VERSION ""

NS_ :

BS_:

BU_:

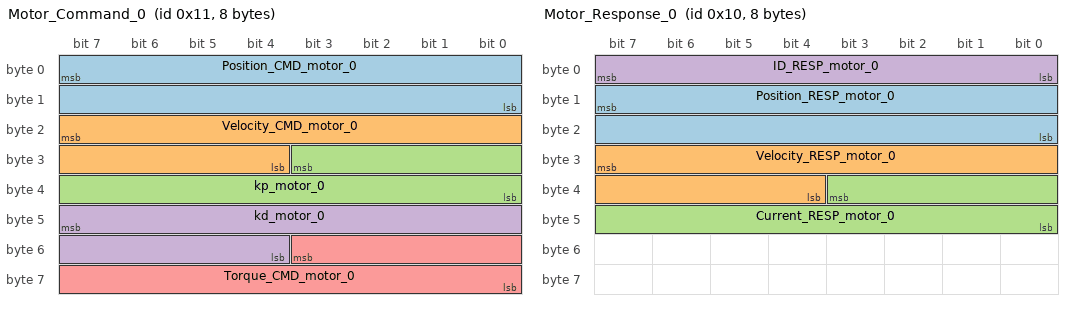
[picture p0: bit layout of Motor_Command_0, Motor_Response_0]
BO_ 17 Motor_Command_0: 8 Vector__XXX
 SG_ Position_CMD_motor_0 : 7|16@0+ (0.002914,-95.5) [0|0] "Rad" Vector__XXX
 SG_ Velocity_CMD_motor_0 : 23|12@0+ (0.02197,-45) [0|0] "Rad/s" Vector__XXX
 SG_ kp_motor_0 : 27|12@0+ (0.1221,0) [0|0] "" Vector__XXX
 SG_ kd_motor_0 : 47|12@0+ (0.001221,0) [0|0] "" Vector__XXX
 SG_ Torque_CMD_motor_0 : 51|12@0+ (0.008791,-18) [0|0] "Nm" Vector__XXX

BO_ 16 Motor_Response_0: 8 Vector__XXX
 SG_ Position_RESP_motor_0 : 15|16@0+ (0.002914,-95.5) [0|0] "Rad" Vector__XXX
 SG_ Velocity_RESP_motor_0 : 31|12@0+ (0.02197,-45) [0|0] "Rad/s" Vector__XXX
 SG_ Current_RESP_motor_0 : 35|12@0+ (0.008791,-18) [0|0] "" Vector__XXX
 SG_ ID_RESP_motor_0 : 7|8@0+ (1,0) [0|0] "" Vector__XXX

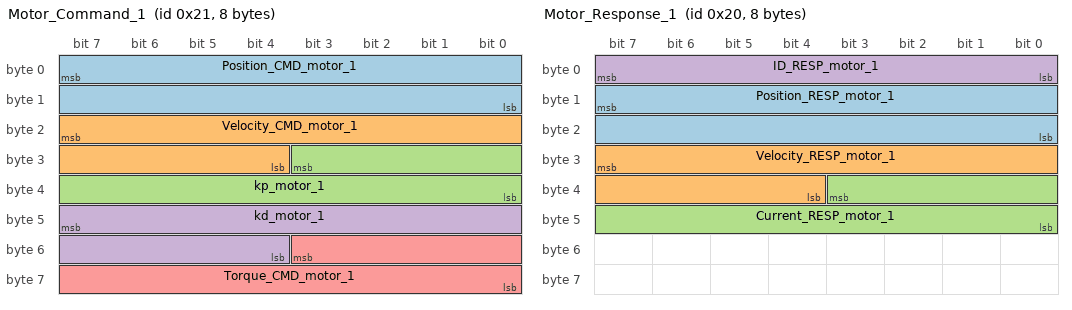
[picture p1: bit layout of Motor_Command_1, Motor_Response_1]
BO_ 33 Motor_Command_1: 8 Vector__XXX
 SG_ Position_CMD_motor_1 : 7|16@0+ (0.002914,-95.5) [0|0] "Rad" Vector__XXX
 SG_ Velocity_CMD_motor_1 : 23|12@0+ (0.02197,-45) [0|0] "Rad/s" Vector__XXX
 SG_ kp_motor_1 : 27|12@0+ (0.1221,0) [0|0] "" Vector__XXX
 SG_ kd_motor_1 : 47|12@0+ (0.001221,0) [0|0] "" Vector__XXX
 SG_ Torque_CMD_motor_1 : 51|12@0+ (0.008791,-18) [0|0] "Nm" Vector__XXX

BO_ 32 Motor_Response_1: 8 Vector__XXX
 SG_ Position_RESP_motor_1 : 15|16@0+ (0.002914,-95.5) [0|0] "Rad" Vector__XXX
 SG_ Velocity_RESP_motor_1 : 31|12@0+ (0.02197,-45) [0|0] "Rad/s" Vector__XXX
 SG_ Current_RESP_motor_1 : 35|12@0+ (0.008791,-18) [0|0] "" Vector__XXX
 SG_ ID_RESP_motor_1 : 7|8@0+ (1,0) [0|0] "" Vector__XXX

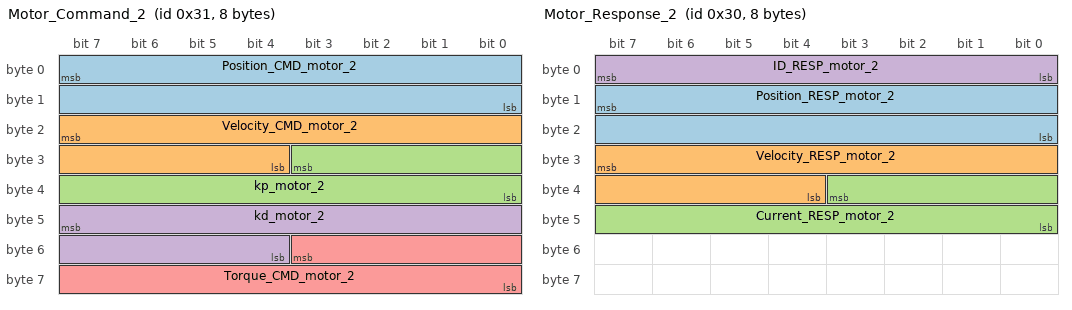
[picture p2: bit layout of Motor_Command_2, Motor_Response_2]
BO_ 49 Motor_Command_2: 8 Vector__XXX
 SG_ Position_CMD_motor_2 : 7|16@0+ (0.002914,-95.5) [0|0] "Rad" Vector__XXX
 SG_ Velocity_CMD_motor_2 : 23|12@0+ (0.02197,-45) [0|0] "Rad/s" Vector__XXX
 SG_ kp_motor_2 : 27|12@0+ (0.1221,0) [0|0] "" Vector__XXX
 SG_ kd_motor_2 : 47|12@0+ (0.001221,0) [0|0] "" Vector__XXX
 SG_ Torque_CMD_motor_2 : 51|12@0+ (0.008791,-18) [0|0] "Nm" Vector__XXX

BO_ 48 Motor_Response_2: 8 Vector__XXX
 SG_ Position_RESP_motor_2 : 15|16@0+ (0.002914,-95.5) [0|0] "Rad" Vector__XXX
 SG_ Velocity_RESP_motor_2 : 31|12@0+ (0.02197,-45) [0|0] "Rad/s" Vector__XXX
 SG_ Current_RESP_motor_2 : 35|12@0+ (0.008791,-18) [0|0] "" Vector__XXX
 SG_ ID_RESP_motor_2 : 7|8@0+ (1,0) [0|0] "" Vector__XXX

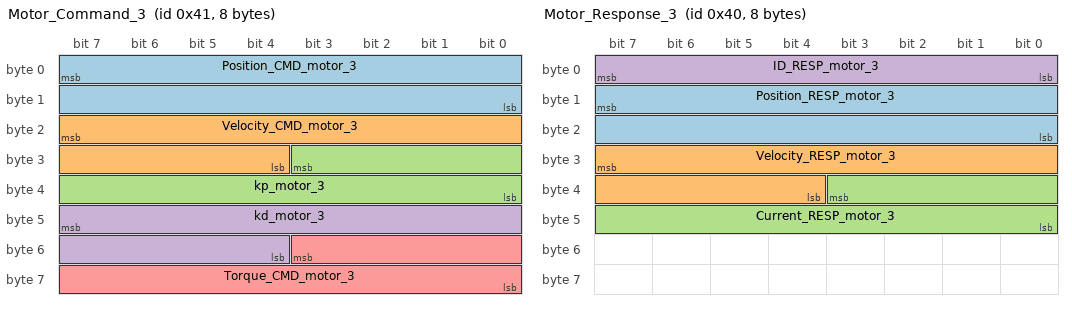
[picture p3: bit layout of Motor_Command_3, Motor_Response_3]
BO_ 65 Motor_Command_3: 8 Vector__XXX
 SG_ Position_CMD_motor_3 : 7|16@0+ (0.002914,-95.5) [0|0] "Rad" Vector__XXX
 SG_ Velocity_CMD_motor_3 : 23|12@0+ (0.02197,-45) [0|0] "Rad/s" Vector__XXX
 SG_ kp_motor_3 : 27|12@0+ (0.1221,0) [0|0] "" Vector__XXX
 SG_ kd_motor_3 : 47|12@0+ (0.001221,0) [0|0] "" Vector__XXX
 SG_ Torque_CMD_motor_3 : 51|12@0+ (0.008791,-18) [0|0] "Nm" Vector__XXX

BO_ 64 Motor_Response_3: 8 Vector__XXX
 SG_ Position_RESP_motor_3 : 15|16@0+ (0.002914,-95.5) [0|0] "Rad" Vector__XXX
 SG_ Velocity_RESP_motor_3 : 31|12@0+ (0.02197,-45) [0|0] "Rad/s" Vector__XXX
 SG_ Current_RESP_motor_3 : 35|12@0+ (0.008791,-18) [0|0] "" Vector__XXX
 SG_ ID_RESP_motor_3 : 7|8@0+ (1,0) [0|0] "" Vector__XXX

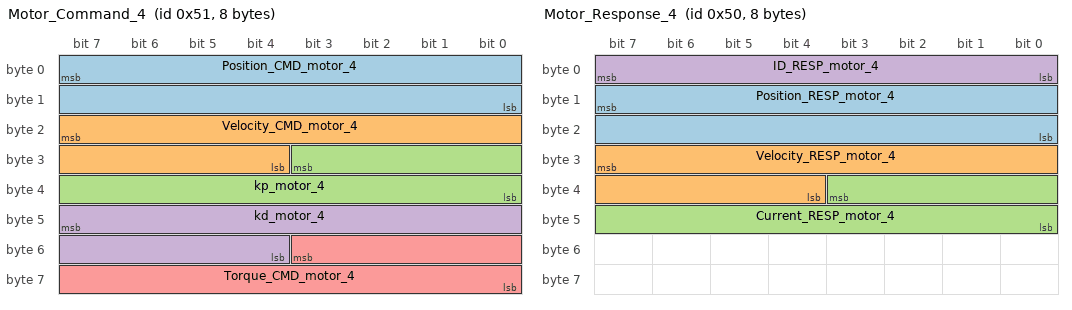
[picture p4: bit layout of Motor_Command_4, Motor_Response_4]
BO_ 81 Motor_Command_4: 8 Vector__XXX
 SG_ Position_CMD_motor_4 : 7|16@0+ (0.002914,-95.5) [0|0] "Rad" Vector__XXX
 SG_ Velocity_CMD_motor_4 : 23|12@0+ (0.02197,-45) [0|0] "Rad/s" Vector__XXX
 SG_ kp_motor_4 : 27|12@0+ (0.1221,0) [0|0] "" Vector__XXX
 SG_ kd_motor_4 : 47|12@0+ (0.001221,0) [0|0] "" Vector__XXX
 SG_ Torque_CMD_motor_4 : 51|12@0+ (0.008791,-18) [0|0] "Nm" Vector__XXX

BO_ 80 Motor_Response_4: 8 Vector__XXX
 SG_ Position_RESP_motor_4 : 15|16@0+ (0.002914,-95.5) [0|0] "Rad" Vector__XXX
 SG_ Velocity_RESP_motor_4 : 31|12@0+ (0.02197,-45) [0|0] "Rad/s" Vector__XXX
 SG_ Current_RESP_motor_4 : 35|12@0+ (0.008791,-18) [0|0] "" Vector__XXX
 SG_ ID_RESP_motor_4 : 7|8@0+ (1,0) [0|0] "" Vector__XXX

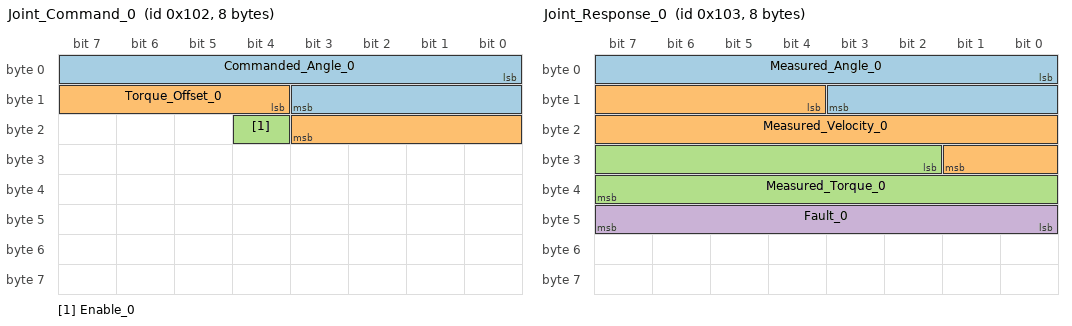
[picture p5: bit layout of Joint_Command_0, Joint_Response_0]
BO_ 258 Joint_Command_0: 8 Vector__XXX
 SG_ Commanded_Angle_0 : 0|12@1- (0.01,0) [0|0] "Rad" Vector__XXX
 SG_ Torque_Offset_0 : 12|8@1- (0.1,0) [0|0] "Nm" Vector__XXX
 SG_ Enable_0 : 20|1@1+ (1,0) [0|0] "" Vector__XXX

BO_ 259 Joint_Response_0: 8 Vector__XXX
 SG_ Measured_Angle_0 : 0|12@1- (0.01,0) [0|0] "Rad" Vector__XXX
 SG_ Measured_Velocity_0 : 12|14@1- (0.01,0) [0|0] "Rad/s" Vector__XXX
 SG_ Measured_Torque_0 : 26|14@1- (0.1,0) [0|0] "Nm" Vector__XXX
 SG_ Fault_0 : 40|8@1+ (1,0) [0|0] "" Vector__XXX

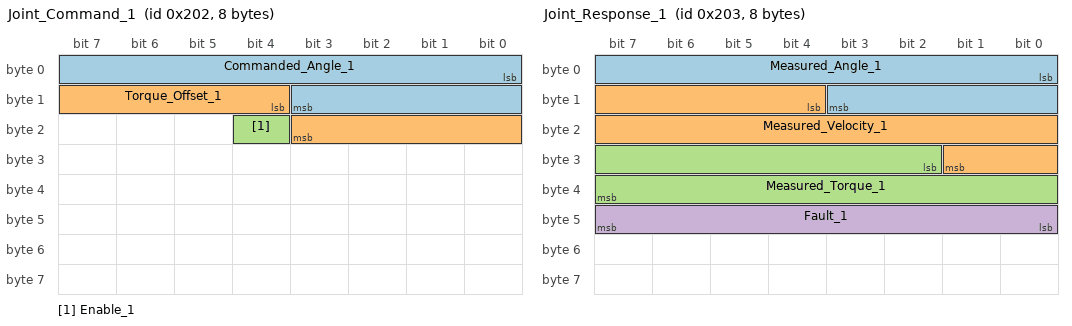
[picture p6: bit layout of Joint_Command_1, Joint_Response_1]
BO_ 514 Joint_Command_1: 8 Vector__XXX
 SG_ Commanded_Angle_1 : 0|12@1- (0.01,0) [0|0] "Rad" Vector__XXX
 SG_ Torque_Offset_1 : 12|8@1- (0.1,0) [0|0] "Nm" Vector__XXX
 SG_ Enable_1 : 20|1@1+ (1,0) [0|0] "" Vector__XXX

BO_ 515 Joint_Response_1: 8 Vector__XXX
 SG_ Measured_Angle_1 : 0|12@1+ (0.1,0) [0|0] "Rad" Vector__XXX
 SG_ Measured_Velocity_1 : 12|14@1- (0.1,0) [0|0] "Rad/s" Vector__XXX
 SG_ Measured_Torque_1 : 26|14@1- (0.1,0) [0|0] "Nm" Vector__XXX
 SG_ Fault_1 : 40|8@1+ (1,0) [0|0] "" Vector__XXX

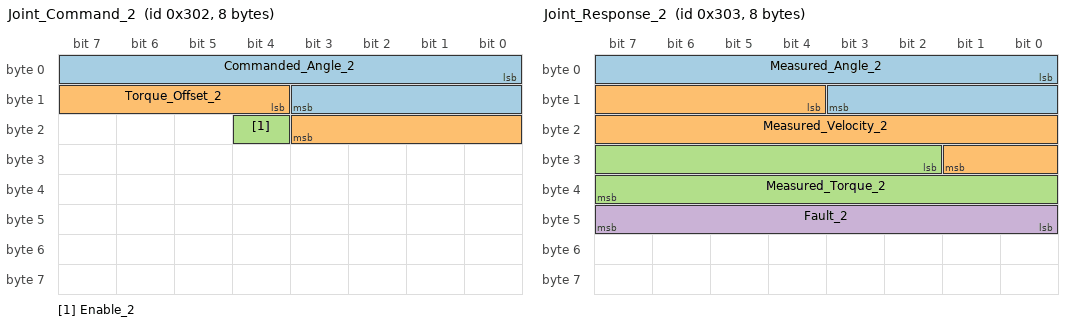
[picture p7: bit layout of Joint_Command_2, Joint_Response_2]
BO_ 770 Joint_Command_2: 8 Vector__XXX
 SG_ Commanded_Angle_2 : 0|12@1- (0.01,0) [0|0] "Rad" Vector__XXX
 SG_ Torque_Offset_2 : 12|8@1- (0.1,0) [0|0] "Nm" Vector__XXX
 SG_ Enable_2 : 20|1@1+ (1,0) [0|0] "" Vector__XXX

BO_ 771 Joint_Response_2: 8 Vector__XXX
 SG_ Measured_Angle_2 : 0|12@1+ (0.1,0) [0|0] "Rad" Vector__XXX
 SG_ Measured_Velocity_2 : 12|14@1- (0.1,0) [0|0] "Rad/s" Vector__XXX
 SG_ Measured_Torque_2 : 26|14@1- (0.1,0) [0|0] "Nm" Vector__XXX
 SG_ Fault_2 : 40|8@1+ (1,0) [0|0] "" Vector__XXX

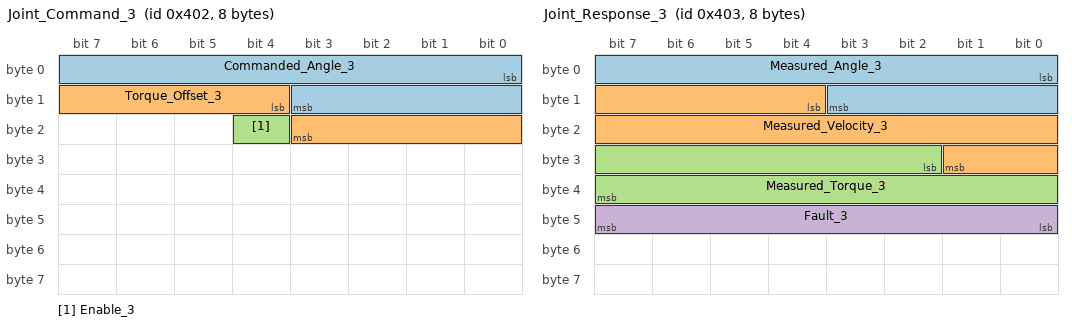
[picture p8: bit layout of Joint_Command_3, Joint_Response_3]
BO_ 1026 Joint_Command_3: 8 Vector__XXX
 SG_ Commanded_Angle_3 : 0|12@1- (0.01,0) [0|0] "Rad" Vector__XXX
 SG_ Torque_Offset_3 : 12|8@1- (0.1,0) [0|0] "Nm" Vector__XXX
 SG_ Enable_3 : 20|1@1+ (1,0) [0|0] "" Vector__XXX

BO_ 1027 Joint_Response_3: 8 Vector__XXX
 SG_ Measured_Angle_3 : 0|12@1+ (0.1,0) [0|0] "Rad" Vector__XXX
 SG_ Measured_Velocity_3 : 12|14@1- (0.1,0) [0|0] "Rad/s" Vector__XXX
 SG_ Measured_Torque_3 : 26|14@1- (0.1,0) [0|0] "Nm" Vector__XXX
 SG_ Fault_3 : 40|8@1+ (1,0) [0|0] "" Vector__XXX

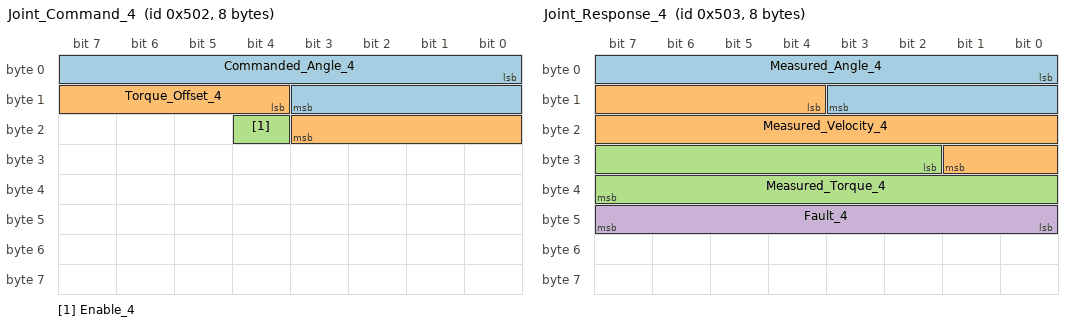
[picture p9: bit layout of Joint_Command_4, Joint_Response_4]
BO_ 1282 Joint_Command_4: 8 Vector__XXX
 SG_ Commanded_Angle_4 : 0|12@1- (0.01,0) [0|0] "Rad" Vector__XXX
 SG_ Torque_Offset_4 : 12|8@1- (0.1,0) [0|0] "Nm" Vector__XXX
 SG_ Enable_4 : 20|1@1+ (1,0) [0|0] "" Vector__XXX

BO_ 1283 Joint_Response_4: 8 Vector__XXX
 SG_ Measured_Angle_4 : 0|12@1+ (0.1,0) [0|0] "Rad" Vector__XXX
 SG_ Measured_Velocity_4 : 12|14@1- (0.1,0) [0|0] "Rad/s" Vector__XXX
 SG_ Measured_Torque_4 : 26|14@1- (0.1,0) [0|0] "Nm" Vector__XXX
 SG_ Fault_4 : 40|8@1+ (1,0) [0|0] "" Vector__XXX

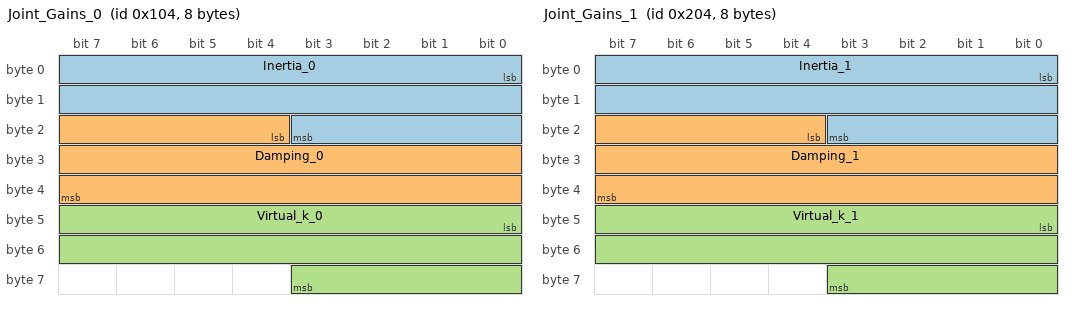
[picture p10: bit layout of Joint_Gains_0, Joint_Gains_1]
BO_ 260 Joint_Gains_0: 8 Vector__XXX
 SG_ Inertia_0 : 0|20@1+ (0.0001,0) [0|0] "" Vector__XXX
 SG_ Damping_0 : 20|20@1+ (0.0001,0) [0|0] "" Vector__XXX
 SG_ Virtual_k_0 : 40|20@1- (0.0001,0) [0|0] "Nm/rad" Vector__XXX

BO_ 516 Joint_Gains_1: 8 Vector__XXX
 SG_ Inertia_1 : 0|20@1+ (0.0001,0) [0|0] "" Vector__XXX
 SG_ Damping_1 : 20|20@1+ (0.0001,0) [0|0] "" Vector__XXX
 SG_ Virtual_k_1 : 40|20@1- (0.0001,0) [0|0] "Nm/rad" Vector__XXX

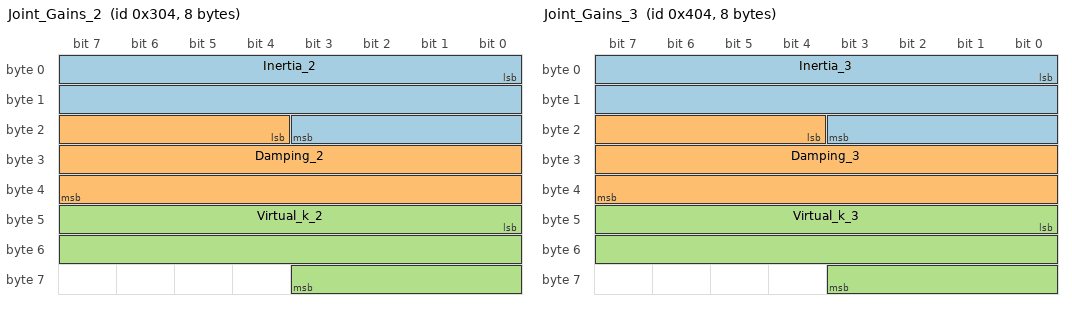
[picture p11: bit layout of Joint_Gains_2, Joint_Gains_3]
BO_ 772 Joint_Gains_2: 8 Vector__XXX
 SG_ Inertia_2 : 0|20@1+ (0.0001,0) [0|0] "" Vector__XXX
 SG_ Damping_2 : 20|20@1+ (0.0001,0) [0|0] "" Vector__XXX
 SG_ Virtual_k_2 : 40|20@1- (0.0001,0) [0|0] "Nm/rad" Vector__XXX

BO_ 1028 Joint_Gains_3: 8 Vector__XXX
 SG_ Inertia_3 : 0|20@1+ (0.0001,0) [0|0] "" Vector__XXX
 SG_ Damping_3 : 20|20@1+ (0.0001,0) [0|0] "" Vector__XXX
 SG_ Virtual_k_3 : 40|20@1- (0.0001,0) [0|0] "Nm/rad" Vector__XXX

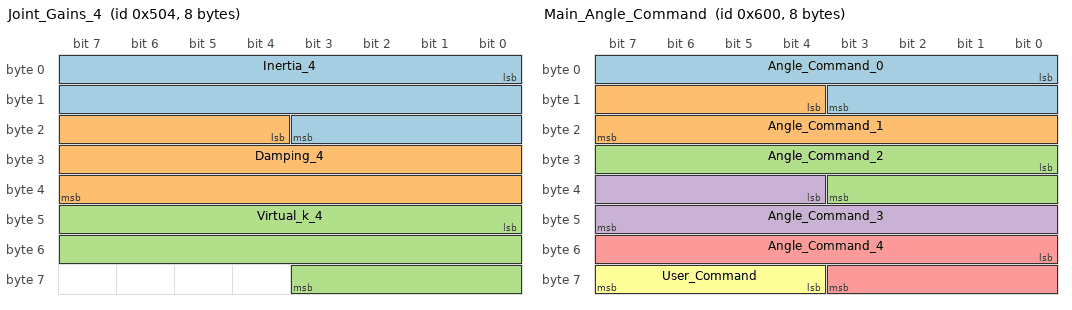
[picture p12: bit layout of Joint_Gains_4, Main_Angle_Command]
BO_ 1284 Joint_Gains_4: 8 Vector__XXX
 SG_ Inertia_4 : 0|20@1+ (0.0001,0) [0|0] "" Vector__XXX
 SG_ Damping_4 : 20|20@1+ (0.0001,0) [0|0] "" Vector__XXX
 SG_ Virtual_k_4 : 40|20@1- (0.0001,0) [0|0] "Nm/rad" Vector__XXX

BO_ 1536 Main_Angle_Command: 8 Vector__XXX
 SG_ Angle_Command_0 : 0|12@1- (0.01,0) [0|0] "Rad" Vector__XXX
 SG_ Angle_Command_1 : 12|12@1- (0.01,0) [0|0] "Rad" Vector__XXX
 SG_ Angle_Command_2 : 24|12@1- (0.01,0) [0|0] "Rad" Vector__XXX
 SG_ Angle_Command_3 : 36|12@1- (0.01,0) [0|0] "Rad" Vector__XXX
 SG_ Angle_Command_4 : 48|12@1- (0.01,0) [0|0] "Rad" Vector__XXX
 SG_ User_Command : 60|4@1+ (1,0) [0|0] "" Vector__XXX

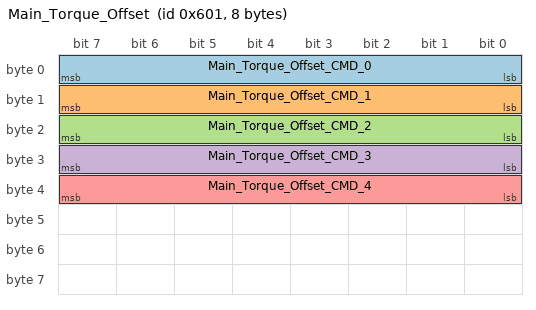
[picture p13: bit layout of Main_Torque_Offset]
BO_ 1537 Main_Torque_Offset: 8 Vector__XXX
 SG_ Main_Torque_Offset_CMD_0 : 0|8@1- (0.1,0) [0|0] "Nm" Vector__XXX
 SG_ Main_Torque_Offset_CMD_1 : 8|8@1- (0.1,0) [0|0] "Nm" Vector__XXX
 SG_ Main_Torque_Offset_CMD_2 : 16|8@1- (0.1,0) [0|0] "Nm" Vector__XXX
 SG_ Main_Torque_Offset_CMD_3 : 24|8@1- (0.1,0) [0|0] "Nm" Vector__XXX
 SG_ Main_Torque_Offset_CMD_4 : 32|8@1- (0.1,0) [0|0] "Nm" Vector__XXX

BO_ 1538 Main_State: 8 Vector__XXX
 SG_ Main_State : 0|8@1+ (1,0) [0|0] "" Vector__XXX

VAL_ 258 Enable_0 0 "Disabled" 1 "Enabled" ;
VAL_ 259 Fault_0 0 "Not_Faulted" 1 "Faulted" ;
VAL_ 514 Enable_1 0 "Disabled" 1 "Enabled" ;
VAL_ 515 Fault_1 0 "Not_Faulted" 1 "Faulted" ;
VAL_ 770 Enable_2 0 "Disabled" 1 "Enabled" ;
VAL_ 771 Fault_2 0 "Not_Faulted" 1 "Faulted" ;
VAL_ 1026 Enable_3 0 "Disabled" 1 "Enabled" ;
VAL_ 1027 Fault_3 0 "Not_Faulted" 1 "Faulted" ;
VAL_ 1282 Enable_4 0 "Disabled" 1 "Enabled" ;
VAL_ 1283 Fault_4 0 "Not_Faulted" 1 "Faulted" ;
VAL_ 1536 User_Command 0 "Stop" 1 "Go" 2 "Clear_Faults" ;
VAL_ 1538 Main_State 0 "Precharge" 1 "Idle" 2 "Run" 3 "Fault" ;
